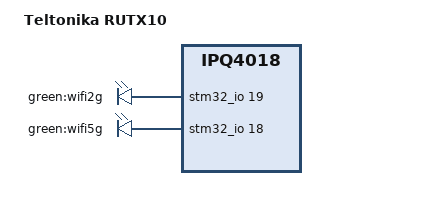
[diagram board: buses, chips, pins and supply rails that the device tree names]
// SPDX-License-Identifier: GPL-2.0-or-later OR MIT

#include "qcom-ipq4018-rutx.dtsi"

/ {
	model = "Teltonika RUTX10";
	compatible = "teltonika,rutx10";

	soc {
		leds {
			compatible = "gpio-leds";

			wifi2g {
				label = "green:wifi2g";
				gpios = <&stm32_io 19 GPIO_ACTIVE_HIGH>;
				linux,default-trigger = "phy0tpt";
			};

			wifi5g {
				label = "green:wifi5g";
				gpios = <&stm32_io 18 GPIO_ACTIVE_HIGH>;
				linux,default-trigger = "phy1tpt";
			};
		};
	};
};
